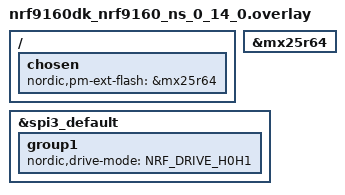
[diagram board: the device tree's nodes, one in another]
/*
 * Copyright (c) 2024 Nordic Semiconductor ASA
 *
 * SPDX-License-Identifier: LicenseRef-Nordic-5-Clause
 */
/* Use the reset line that is available starting from v0.14.0 of the DK. */
#include <nrf9160/nrf9160dk_nrf52840_reset_on_if9.dtsi>

/ {
	chosen {
		nordic,pm-ext-flash = &mx25r64;
	};
};

/* External flash device is disabled by default */
&mx25r64 {
	status = "okay";
};

/* Enable high drive mode for the SPI3 pins to get a square signal at 8 MHz */
&spi3_default {
	group1 {
		nordic,drive-mode = <NRF_DRIVE_H0H1>;
	};
};
